# PIC16LF1567 register map
Vendor: Microchip
Registers are 8-bit, read-write, no defined reset value unless marked. A register's access mark holds for its fields unless they carry their own. Addresses are absolute, and some are shared; only a register's first bit layout is shown; [hi:lo] are bit positions; {n}, {i} and the like mark numbered series.

## SFR
0x00 INDF0 — (power-on value xxxxxxxx)
0x01 INDF1 — (power-on value xxxxxxxx)
0x02 PCL reset 0x0
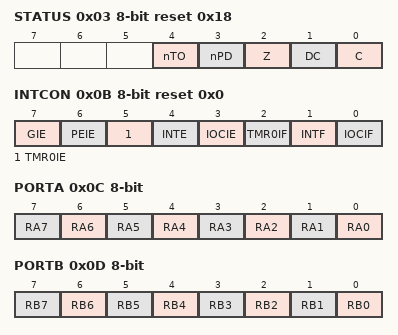
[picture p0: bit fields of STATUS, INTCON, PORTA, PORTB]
0x03 STATUS reset 0x18
  [4] nTO ro — Time-out Bit
    1=After power-up, CLRWDT instruction, or SLEEP instruction; 0=A WDT time-out occurred
  [3] nPD ro — Power-down Bit
    1=After power-up or by the CLRWDT instruction; 0=By execution of the SLEEP instruction
  [2] Z — Zero bit
    1=The result of an arithmetic or logic operation is zero; 0=The result of an arithmetic or logic operation is not zero
  [1] DC — Digit Carry / Digit Borrow bit
    1=A carry-out from the 4th low-order bit of the result occurred; 0=No carry-out from the 4th low-order bit of the result occurred
  [0] C — Carry / Borrow bit
    1=A carry-out from the Most Significant bit of the result occurred; 0=No carry-out from the Most Significant bit of the result occurred
0x04 FSR0L reset 0x0
0x05 FSR0H reset 0x0
0x06 FSR1L reset 0x0
0x07 FSR1H reset 0x0
0x08 BSR reset 0x0
  [4:0] BSR
0x09 WREG reset 0x0
  [7:0] WREG0
0x0A PCLATH reset 0x0
  [6:0] PCLATH
0x0B INTCON reset 0x0
  [7] GIE — Global Interrupt Enable
    1=Enables all unmasked interrupts; 0=Disables all interrupts
  [6] PEIE — Peripheral Interrupt Enable
    1=Enables all unmasked peripheral interrupts; 0=Disables all peripheral interrupts
  [5] TMR0IE — TMR0 Overflow Interrupt Enable
    1=Enables the TMR0 interrupt; 0=Disables the TMR0 interrupt
  [4] INTE — INT External Interrupt Enable
    1=Enables the INT external interrupt; 0=Disables the INT external interrupt
  [3] IOCIE — Interrupt-on-Change Enable
    1=Enables the interrupt-on-change; 0=Disables the interrupt-on-change
  [2] TMR0IF — Timer0 Overflow Interrupt Flag
    1=TMR0 register has overflowed; 0=TMR0 register did not overflow
  [1] INTF — INT External Interrupt Flag
    1=The INT external interrupt occurred; 0=The INT external interrupt did not occur
  [0] IOCIF ro — Interrupt-on-Change Interrupt Flag
    1=When at least one of the interrupt-on-change pins changed state; 0=None of the interrupt-on-change pins have changed state
0x0C PORTA — (power-on value xxxxxxxx)
  [n] RA{n} (n=0..7)
0x0D PORTB — (power-on value xxxxxxxx)
  [n] RB{n} (n=0..7)
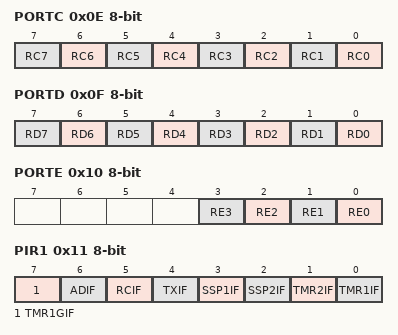
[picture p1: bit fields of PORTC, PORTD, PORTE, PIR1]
0x0E PORTC — (power-on value xxxxxxxx)
  [n] RC{n} (n=0..7)
0x0F PORTD — (power-on value xxxxxxxx)
  [n] RD{n} (n=0..7)
0x10 PORTE — (power-on value ----xxxx)
  [n] RE{n} (n=0..3)
0x11 PIR1 — (power-on value 00000x00)
  [7] TMR1GIF — Timer1 Gate Interrupt Flag bit
  [6] ADIF — A/D Converter 1 Interrupt Flag bit
  [5] RCIF ro — EUSART Receive Interrupt Enable bit
  [4] TXIF ro — EUSART Transmit Interrupt Enable bit
  [3] SSP1IF — Synchronous Serial Port (MSSP) Interrupt Flag bit
  [2] SSP2IF
  [1] TMR2IF — TMR2 to PR2 Match Interrupt Flag bit
  [0] TMR1IF — TMR1 Overflow Interrupt Flag bit
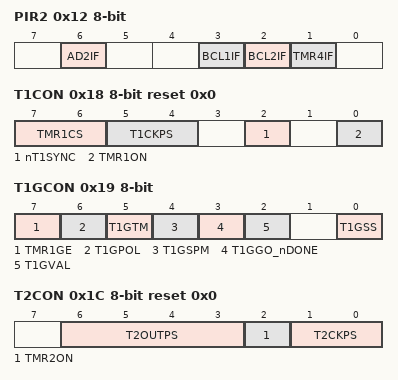
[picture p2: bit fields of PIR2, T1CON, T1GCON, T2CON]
0x12 PIR2 — (power-on value -0--0xx-)
  [6] AD2IF — A/D Converter 2 Interrupt Flag bit
  [3] BCL1IF — MSSP Bus Collision Interrupt Flag bit
  [2] BCL2IF
  [1] TMR4IF
0x15 TMR0 — (power-on value xxxxxxxx)
0x16 TMR1L — (power-on value xxxxxxxx)
0x17 TMR1H — (power-on value xxxxxxxx)
0x18 T1CON reset 0x0 — Timer 1 Control
  [7:6] TMR1CS — Timer1 Clock Source Select
  [5:4] T1CKPS — Timer1 Input Clock Prescale Select
  [2] nT1SYNC — Timer1 External Clock Input Synchronization Control
  [0] TMR1ON — Timer1 On
0x19 T1GCON — Timer 1 Gate Control (power-on value 00000x-0)
  [7] TMR1GE, [6] T1GPOL, [5] T1GTM, [4] T1GSPM, [3] T1GGO_nDONE, [2] T1GVAL ro, [0] T1GSS
0x1A TMR2 reset 0x0
0x1B PR2 reset 0xFF
0x1C T2CON reset 0x0
  [6:3] T2OUTPS — Timer2 Output Postscaler Select
  [2] TMR2ON — Timer2 On
  [1:0] T2CKPS — Timer2 Clock Prescale Select
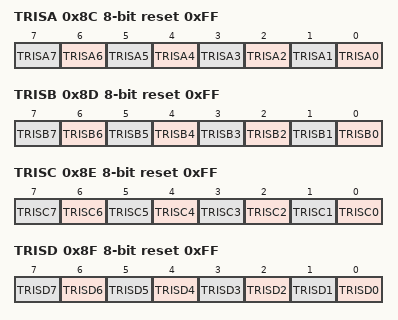
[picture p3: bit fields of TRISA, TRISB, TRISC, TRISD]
0x8C TRISA reset 0xFF — PORTA Data Direction Control Register
  [n] TRISA{n} (n=0..7)
0x8D TRISB reset 0xFF
  [n] TRISB{n} (n=0..7)
0x8E TRISC reset 0xFF — PORTC Data Direction Control Register
  [n] TRISC{n} (n=0..7)
0x8F TRISD reset 0xFF — PORTC Data Direction Control Register
  [n] TRISD{n} (n=0..7)
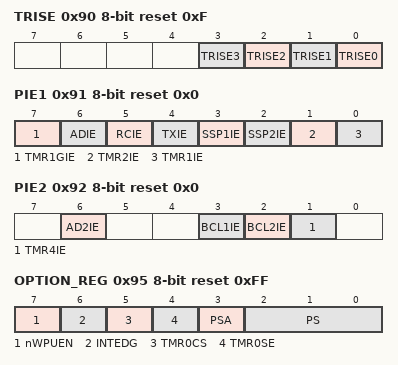
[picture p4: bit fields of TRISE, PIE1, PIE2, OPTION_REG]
0x90 TRISE reset 0xF — PORTC Data Direction Control Register
  [n] TRISE{n} (n=0..3)
0x91 PIE1 reset 0x0 — Peripheral Interrupt Enable Register 1
  [7] TMR1GIE — Timer1 Gate Interrupt Enable bit
  [6] ADIE — A/D Converter Interrupt Enable bit
  [5] RCIE
  [4] TXIE
  [3] SSP1IE
  [2] SSP2IE
  [1] TMR2IE — TMR2 to PR2 Match Interrupt Enable bit
  [0] TMR1IE — TMR1 Overflow Interrupt Enable bit
0x92 PIE2 reset 0x0 — Peripheral Interrupt Enable Register 2
  [6] AD2IE, [3] BCL1IE, [2] BCL2IE, [1] TMR4IE
0x95 OPTION_REG reset 0xFF — Option Register
  [7] nWPUEN — Weak Pull-up Enable bit
  [6] INTEDG — Interrupt Edge Select bit
  [5] TMR0CS
  [4] TMR0SE — TMR0 Source Edge Select bit
  [3] PSA — Prescaler Active bit
  [2:0] PS
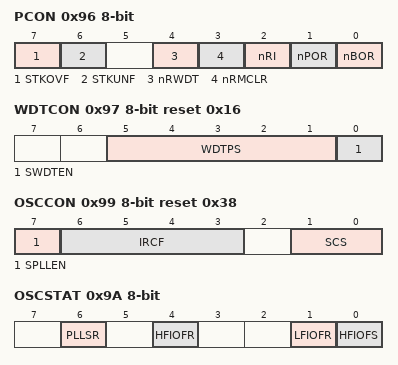
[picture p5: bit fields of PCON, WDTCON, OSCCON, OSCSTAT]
0x96 PCON — Power Control Register (power-on value 00-111qq)
  [7] STKOVF — Stack Overflow Flag bit
  [6] STKUNF — Stack Underflow Flag bit
  [4] nRWDT
  [3] nRMCLR — MCLR Reset Flag bit
  [2] nRI — RESET Instruction Flag bit
  [1] nPOR — Power-on Reset Status bit
  [0] nBOR — Brown-out Reset Status bit
0x97 WDTCON reset 0x16 — Watchdog Timer Control Register
  [5:1] WDTPS
  [0] SWDTEN — Software Enable/Disable for Watch Dog Timer bit
0x99 OSCCON reset 0x38 — Oscillator Control Register
  [7] SPLLEN, [6:3] IRCF, [1:0] SCS
0x9A OSCSTAT ro — Oscillator Status Register (power-on value -0-0--0q)
  [6] PLLSR
  [4] HFIOFR
  [1] LFIOFR — Low Freqency Internal Oscillator Ready bit
  [0] HFIOFS — Low Freqency Internal Oscillator Ready bit
0x9B ADRESL — A/D Result Register LSB (power-on value xxxxxxxx)
0x9C ADRESH — A/D Result Register MSB (power-on value xxxxxxxx)
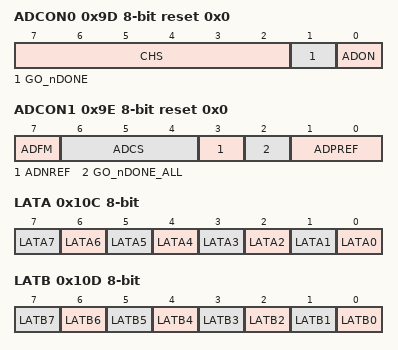
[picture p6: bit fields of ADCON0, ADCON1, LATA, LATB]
0x9D ADCON0 reset 0x0 — Analog-to-Digital Control Register 0
  [7:2] CHS
  [1] GO_nDONE — A/D Conversion Status bit
  [0] ADON — A/D Module Enable bit
0x9E ADCON1 reset 0x0 — Analog-to-Digital Control Register 1
  [7] ADFM — A/D Result Format Select bit
  [6:4] ADCS
  [3] ADNREF
  [2] GO_nDONE_ALL
  [1:0] ADPREF
0x9F ADCON2 reset 0x0 — Analog-to-Digital Control Register 2
  [6:4] TRIGSEL
0x10C LATA — (power-on value xxxxxxxx)
  [n] LATA{n} (n=0..7)
0x10D LATB — (power-on value xxxxxxxx)
  [n] LATB{n} (n=0..7)
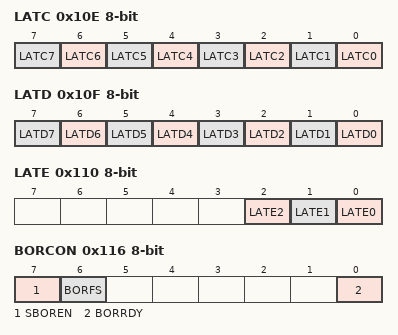
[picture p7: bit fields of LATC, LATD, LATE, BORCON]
0x10E LATC — (power-on value xxxxxxxx)
  [n] LATC{n} (n=0..7)
0x10F LATD — (power-on value xxxxxxxx)
  [n] LATD{n} (n=0..7)
0x110 LATE — (power-on value -----xxx)
  [2] LATE2, [1] LATE1, [0] LATE0
0x116 BORCON — Brown-out Reset Control Register (power-on value 10-----q)
  [7] SBOREN — Software Brown Out Reset Enable bit
  [6] BORFS
  [0] BORRDY ro — Brown-out Reset Circuit Ready Status bit
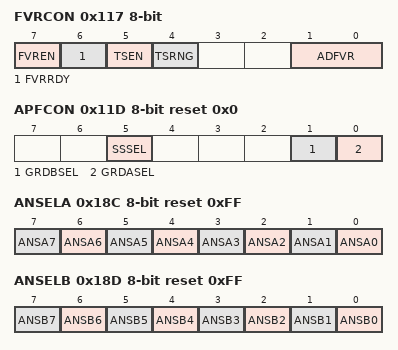
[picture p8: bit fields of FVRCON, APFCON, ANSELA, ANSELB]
0x117 FVRCON — Voltage Reference Control Register 0 (power-on value 0q00--00)
  [7] FVREN — Fixed Voltage Reference Enable
  [6] FVRRDY ro — Fixed Voltage Reference Ready Flag
  [5] TSEN — Temperature Sensor Enable
  [4] TSRNG — Temperature Sensor Range Select
  [1:0] ADFVR — A/D Converter Fixed Voltage Reference Selection
0x11D APFCON reset 0x0 — Alternate Pin Function Control Register
  [5] SSSEL, [1] GRDBSEL, [0] GRDASEL
0x18C ANSELA reset 0xFF
  [n] ANSA{n} (n=0..7)
0x18D ANSELB reset 0xFF
  [n] ANSB{n} (n=0..7)
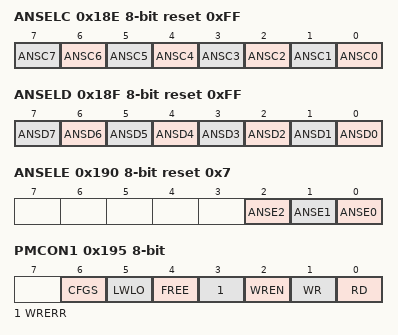
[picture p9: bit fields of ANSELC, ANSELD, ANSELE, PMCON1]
0x18E ANSELC reset 0xFF
  [n] ANSC{n} (n=0..7)
0x18F ANSELD reset 0xFF
  [n] ANSD{n} (n=0..7)
0x190 ANSELE reset 0x7
  [2] ANSE2, [1] ANSE1, [0] ANSE0
0x191 PMADRL reset 0x0
0x192 PMADRH reset 0x80
  [6:0] PMADRH
0x193 PMDATL — (power-on value xxxxxxxx)
0x194 PMDATH — (power-on value --xxxxxx)
  [5:0] PMDATH
0x195 PMCON1 — (power-on value -000x000)
  [6] CFGS — FLASH Program / Configuration Select bit
  [5] LWLO — Load Write Latches Only bit
  [4] FREE — Program FLASH Erase Enable bit
  [3] WRERR — Sequence Error Flag bit
  [2] WREN — Program/Erase Enable bit
  [1] WR — Write Control bit (can only be set)
  [0] RD — Read Control bit (can only be set)
0x196 PMCON2 wo reset 0x0
0x199 RCREG — (power-on value xxxxxxxx)
0x19A TXREG — (power-on value xxxxxxxx)
0x19B SPBRGL — (power-on value xxxxxxxx)
0x19C SPBRGH — (power-on value xxxxxxxx)
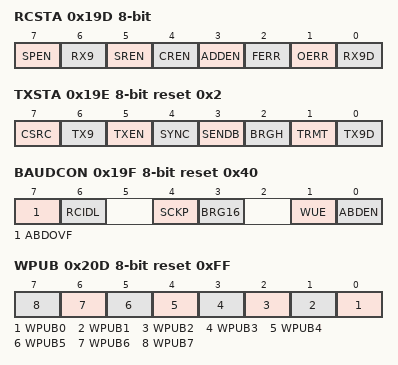
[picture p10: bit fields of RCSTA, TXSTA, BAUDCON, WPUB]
0x19D RCSTA — (power-on value 0000000x)
  [7] SPEN, [6] RX9, [5] SREN, [4] CREN, [3] ADDEN, [2] FERR ro, [1] OERR ro, [0] RX9D ro
0x19E TXSTA reset 0x2 — Transmit Status and Control Register
  [7] CSRC, [6] TX9, [5] TXEN, [4] SYNC, [3] SENDB, [2] BRGH, [1] TRMT ro, [0] TX9D
0x19F BAUDCON reset 0x40 — Baud Rate Control Register
  [7] ABDOVF ro, [6] RCIDL ro, [4] SCKP, [3] BRG16, [1] WUE, [0] ABDEN
0x20D WPUB reset 0xFF
  [n] WPUB{n} (n=0..7)
0x210 WPUE reset 0x8
  [3] WPUE3
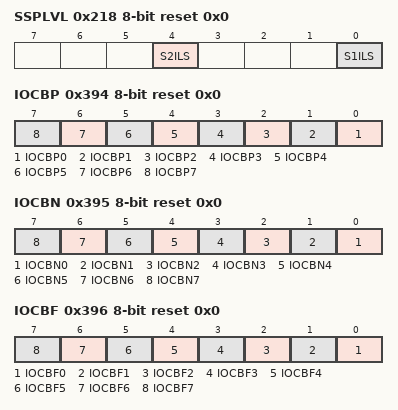
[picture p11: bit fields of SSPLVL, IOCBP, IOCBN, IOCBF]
0x218 SSPLVL reset 0x0
  [4] S2ILS, [0] S1ILS
0x394 IOCBP reset 0x0
  [n] IOCBP{n} (n=0..7)
0x395 IOCBN reset 0x0
  [n] IOCBN{n} (n=0..7)
0x396 IOCBF reset 0x0
  [n] IOCBF{n} (n=0..7)
0x415 TMR4 reset 0x0
0x416 PR4 reset 0xFF
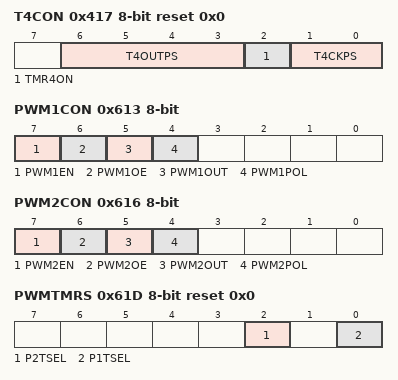
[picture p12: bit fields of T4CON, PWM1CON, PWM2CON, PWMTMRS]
0x417 T4CON reset 0x0
  [6:3] T4OUTPS, [2] TMR4ON, [1:0] T4CKPS
0x611 PWM1DCL — (power-on value xx------)
  [7:6] PWM1DCL
0x612 PWM1DCH — (power-on value xxxxxxxx)
0x613 PWM1CON — Configurable logic cell control (power-on value 00x0----)
  [7] PWM1EN, [6] PWM1OE, [5] PWM1OUT ro, [4] PWM1POL
0x614 PWM2DCL — (power-on value xx------)
  [7:6] PWM2DCL
0x615 PWM2DCH — (power-on value xxxxxxxx)
0x616 PWM2CON — Configurable logic cell control (power-on value 00x0----)
  [7] PWM2EN, [6] PWM2OE, [5] PWM2OUT ro, [4] PWM2POL
0x61D PWMTMRS reset 0x0
  [2] P2TSEL, [0] P1TSEL
0x61E PWM1AOE reset 0x0
  [3:0] PWM1OE
0x61F PWM2AOE reset 0x0
  [3:0] PWM2OE
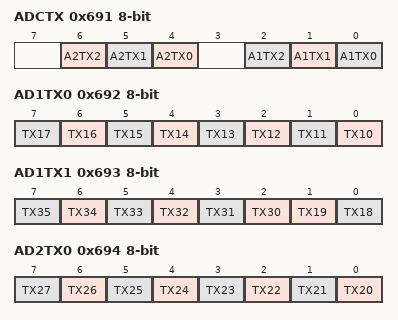
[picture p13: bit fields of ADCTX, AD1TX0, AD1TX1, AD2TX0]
0x691 ADCTX — (power-on value -xxx-xxx)
  [6] A2TX2, [5] A2TX1, [4] A2TX0, [2] A1TX2, [1] A1TX1, [0] A1TX0
0x692 AD1TX0 — (power-on value xxxxxxxx)
  [n-10] TX{n} (n=10..17)
0x693 AD1TX1 — (power-on value xxxxxxxx)
  [n-28] TX{n} (n=30..35), [1] TX19, [0] TX18
0x694 AD2TX0 — (power-on value xxxxxxxx)
  [n-20] TX{n} (n=20..27)
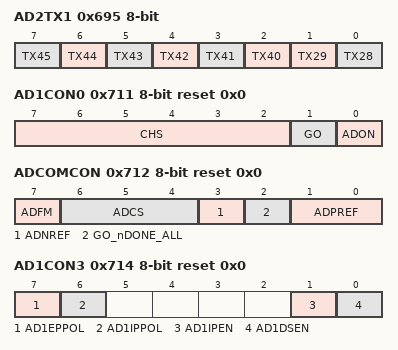
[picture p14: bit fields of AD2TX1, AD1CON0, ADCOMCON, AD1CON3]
0x695 AD2TX1 — (power-on value xxxxxxxx)
  [n-38] TX{n} (n=40..45), [1] TX29, [0] TX28
0x711 AD1CON0 reset 0x0
  [7:2] CHS, [1] GO, [0] ADON
0x712 ADCOMCON reset 0x0
  [7] ADFM, [6:4] ADCS, [3] ADNREF, [2] GO_nDONE_ALL, [1:0] ADPREF
0x713 AD1CON2 reset 0x0
  [6:4] TRIGSEL
0x714 AD1CON3 reset 0x0
  [7] AD1EPPOL, [6] AD1IPPOL, [1] AD1IPEN, [0] AD1DSEN
0x715 ADSTAT ro reset 0x0
  [6] AD2CONV, [5:4] AD2STG, [2] AD1CONV, [1:0] AD1STG
0x716 AD1PRECON reset 0x0
  [6:0] ADPRE
0x717 AD1ACQCON reset 0x0
  [6:0] ADACQ
0x718 AD1GRD reset 0x0
  [7] GRD1BOE, [6] GRD1AOE, [5] GRD1POL, [0] TX1POL
0x719 AD1CAPCON reset 0x0
  [3:0] ADDCAP
0x71A AAD1RES0L — (power-on value xxxxxxxx)
  [7:0] ADRESL
0x71B AAD1RES0H — (power-on value xxxxxxxx)
  [7:0] ADRESH
0x71C AAD1RES1L — (power-on value xxxxxxxx)
  [7:0] ADRESL
0x71D AAD1RES1H — (power-on value xxxxxxxx)
  [7:0] ADRESH
0x71E AD1CH0 reset 0x0
  [7] CHS17, [n-10] CH{n} (n=10..16)
0x71F AD1CH1 reset 0x0
  [n-28] CH{n} (n=30..35), [1] CH19, [0] CH18
0x791 AD2CON0 reset 0x0
  [7:2] CHS, [1] GO, [0] ADON
0x793 AD2CON2 reset 0x0
  [6:4] TRIGSEL
0x794 AD2CON3 reset 0x0
  [7] AD2EPPOL, [6] AD2IPPOL, [1] AD2IPEN, [0] AD2DSEN
0x796 AD2PRECON reset 0x0
  [6:0] ADPRE
0x797 AD2ACQCON reset 0x0
  [6:0] ADACQ
0x798 AD2GRD — (power-on value 000----x)
  [7] GRD2BOE, [6] GRD2AOE, [5] GRD2POL, [0] TX2POL
0x799 AD2CAPCON reset 0x0
  [3:0] ADDCAP
0x79A AAD2RES0L — (power-on value xxxxxxxx)
  [7:0] ADRESL
0x79B AAD2RES0H — (power-on value xxxxxxxx)
  [7:0] ADRESH
0x79C AAD2RES1L — (power-on value xxxxxxxx)
  [7:0] ADRESL
0x79D AAD2RES1H — (power-on value xxxxxxxx)
  [7:0] ADRESH
0x79E AD2CH0 reset 0x0
  [n-20] CH{n} (n=20..27)
0x79F AD2CH1 reset 0x0
  [n-38] CH{n} (n=40..45), [1] CH29, [0] CH28
0xF8C ICDIO — (power-on value xxxxxx--)
  [7] PORT_ICDDAT, [6] PORT_ICDCLK, [5] LAT_ICDDAT, [4] LAT_ICDCLK, [3] TRIS_ICDDAT, [2] TRIS_ICDCLK
0xF8D ICDCON0 — (power-on value xxx-x--x)
  [7] INBUG, [6] FREEZ, [5] SSTEP, [3] DBGINEX, [0] RSTVEC
0xF91 ICDSTAT — (power-on value xx----x-)
  [7] TRP1HLTF, [6] TRP0HLTF, [1] USRHLTF
0xF96 ICDINSTL — (power-on value xxxxxxxx)
  [n] DBGIN{n} (n=0..7)
0xF97 ICDINSTH — (power-on value --xxxxxx)
  [n-8] DBGIN{n} (n=8..13)
0xF9C ICDBK0CON — (power-on value x------x)
  [7] BKEN, [0] BKHLT
0xF9D ICDBK0L — (power-on value xxxxxxxx)
  [n] BKA{n} (n=0..7)
0xF9E ICDBK0H — (power-on value -xxxxxxx)
  [n-8] BKA{n} (n=8..14)
0xFE3 BSRICDSHAD — (power-on value ---xxxxx)
  [4:0] BSR_ICDSHAD
0xFE4 STATUS_SHAD — (power-on value -----xxx)
  [2] Z_SHAD, [1] DC_SHAD, [0] C_SHAD
0xFE5 WREG_SHAD — (power-on value xxxxxxxx)
0xFE6 BSR_SHAD — (power-on value ---xxxxx)
  [4:0] BSR_SHAD
0xFE7 PCLATH_SHAD — (power-on value -xxxxxxx)
  [6:0] PCLATH_SHAD
0xFE8 FSR0L_SHAD — (power-on value xxxxxxxx)
0xFE9 FSR0H_SHAD — (power-on value xxxxxxxx)
0xFEA FSR1L_SHAD — (power-on value xxxxxxxx)
0xFEB FSR1H_SHAD — (power-on value xxxxxxxx)
0xFED STKPTR reset 0x1F — Current Stack pointer
  [4:0] STKPTR
0xFEE TOSL — Top of Stack Low byte (power-on value xxxxxxxx)
0xFEF TOSH — Top of Stack High byte (power-on value -xxxxxxx)
  [6:0] TOSH
